# wl_phy_ctrl_secure register map
Vendor: Texas Instruments
Peripheral module from a debugger description file (folder CC35X1E).
Registers are 32-bit, access per field, no defined reset value unless marked. A register's access mark holds for its fields unless they carry their own. Offsets are as the file gives them; lines under a group give offsets from that group; [hi:lo] are bit positions; {n}, {i} and the like mark numbered series; 'fields as' and 'values as' point back to an identical list; <NAME> marks a mode.

## wl_phy_ctrl_secure
0x00 scr_src_addr reset 0x0 — Internal scripter registers affect the scripter on-going behavior.
  [15:0] MEM_SRC_ADDR_WROPT rw — Defines the current script base address. The scripter fetch bus will read consecutive rows from this address in increments of 4.
0x04 scr_dest_rd_offset_addr — Scripter Destination offset address
  [15:0] MEM_DEST_RD_OFFSET_ADDR rw — Set destination read address bits [31:16]. 4590 - PHY MCU RAMs 4591 - PHY MCU SCR RAM and Regs 4592 - PHY OCP interConnect components but MCU. Other - To SOC
0x08 scr_data_bit_sel reset 0x0 — Data bit select
  [15:0] MEM_DATA_BIT_SEL_WROPT rw — This field has 2 purposes: 1. Set the bits that will be changed in the next read modify write command. 2. Set the bits that will be checked in the next conditional write command.
0x0C scr_data_match reset 0xFFFF — Matching value for conditional write command.
  [15:0] MEM_DATA_MATCH_WROPT rw — This register is used for conditional write operations. This register needs to be defined and then a variable value is read and compared (according to the bits set in the data_bit_sel register). (Set the matching value for the next conditional write command)
0x10 scr_spare_1 reset 0x0
  [7:0] MEM_SCR_SPARE_1 rw
0x14 scr_wait_delay — Scripter Wait Delay Register
  [15:0] MEM_WAIT_DELAY_WROPT rw — Once this register is set to a non-zero value the scripter exe bus is suspended untill it decrements all the way back to zero.
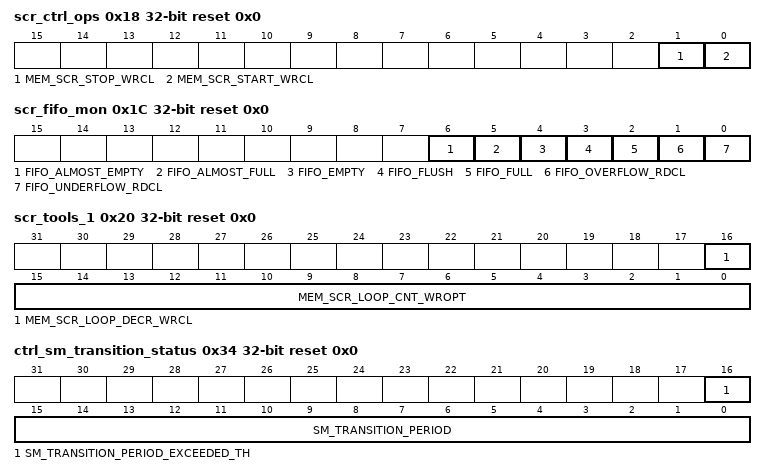
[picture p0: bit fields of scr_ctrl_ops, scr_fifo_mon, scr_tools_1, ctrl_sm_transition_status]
0x18 scr_ctrl_ops reset 0x0
  [1] MEM_SCR_STOP_WRCL wo — This bit must be set at the end of any script. It may also be used to abort a running script externally by FW.
  [0] MEM_SCR_START_WRCL wo — This pulse bit allows the FW to trigger the start of a script. The FW needs to per-set the value of the src_addr register.
0x1C scr_fifo_mon ro reset 0x0
  [6] FIFO_ALMOST_EMPTY, [5] FIFO_ALMOST_FULL, [4] FIFO_EMPTY, [3] FIFO_FLUSH, [2] FIFO_FULL, [1] FIFO_OVERFLOW_RDCL, [0] FIFO_UNDERFLOW_RDCL
0x20 scr_tools_1 reset 0x0
  [16] MEM_SCR_LOOP_DECR_WRCL wo, [15:0] MEM_SCR_LOOP_CNT_WROPT rw
0x24 scr_dest_wr_offset_addr — Scripter Destination offset address
  [15:0] MEM_DEST_WR_OFFSET_ADDR rw — Set destination write address bits [31:16]. 4590 - PHY MCU RAMs 4591 - PHY MCU SCR RAM and Regs 4592 - PHY OCP interConnect components but MCU. Other - To SOC
0x30 ctrl_sm_transition_threshold reset 0x1002
  [10:0] MEM_TRANSITION_TIME_TRACK_TH rw — Event Executer (cortex, scripter or both) transition time limit. When executer exeedes this value, SM_TRANSITION_PERIOD_EXCEEDED_TH is set high (clr by s/w). Counts up to 102.4us. Resolution is 0.8us. Default ix 0x2 (1.6us).
0x34 ctrl_sm_transition_status ro reset 0x0
  [16] SM_TRANSITION_PERIOD_EXCEEDED_TH — This indication is set when: SM_TRANSITION_PERIOD[in 25ns units]> SM_TRANSITION_PERIOD_TH
  [15:0] SM_TRANSITION_PERIOD — the period of time that is measured from the time an event is sent to cortex/scripter till the time cortex/scripter is done and phy state is changed. Time is measured at 25ns*32=800ns units (1.25M rate) (as if you concate 5 LSB equal to '0' on the right side of this number.)
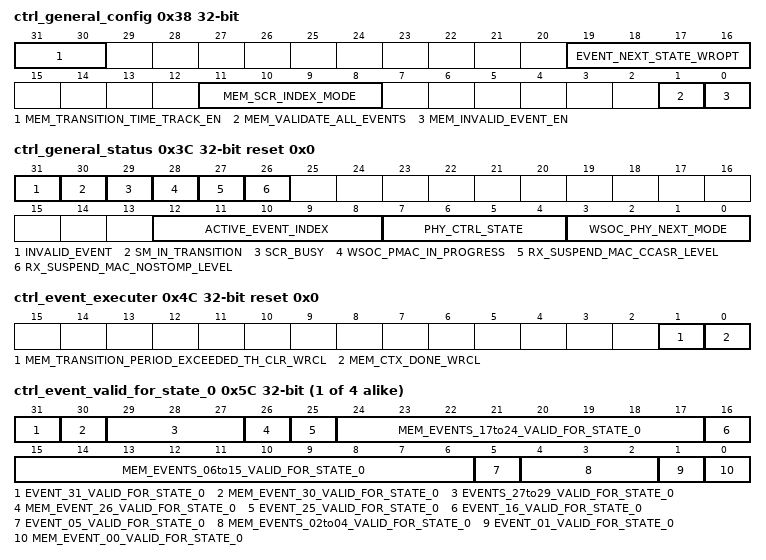
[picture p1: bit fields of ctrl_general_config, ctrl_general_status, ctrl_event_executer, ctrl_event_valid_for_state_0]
0x38 ctrl_general_config
  [31:30] MEM_TRANSITION_TIME_TRACK_EN rw — 00 - Do not measure transition time 01 - Measure CTX transition time 10 - Measure SCR transition time 11 - Measure CTX or SCR transition time (if both are excuted, measure till the last one finishes) note: time is measured @40M rate (each unit is 25ns)
  [19:16] EVENT_NEXT_STATE_WROPT rw — PHY Control FSM Bypass: This field will be loaded to PHY STATE immediately at acripter/cortex done. It replaces the default h/w next_state (that is selected per event at "evet start") .
  [11:8] MEM_SCR_INDEX_MODE rw — this mode controls the ADDR reg in SCR: 0 - ADDR is fetched from Upper-half[15:0] 1 - ADDR is fetched from Upper-half[31:16] 2 - ADDR is fetched from Lower-half[15:0] 3 - ADDR is fetched from Lower-half[31:16]
  [1] MEM_VALIDATE_ALL_EVENTS rw — '0' - invalid event will be ganarated according to event valid bit map (MEM_EVENT_VALID_FOR_STATE0..8) '1' - No invalid event support. All events are valid at any state regardless tovalid bit map.
  [0] MEM_INVALID_EVENT_EN rw — '0' - invalid event is not enabled. will not be sent to cortex. '1' - invalid event is enabled. will be sent to cortex.
0x3C ctrl_general_status ro reset 0x0
  [31] INVALID_EVENT — indication that invalid event is sent to cortex. This means that INVALID_EVENT_EN was set to 1.
  [30] SM_IN_TRANSITION — indication that an event is sent to cortex/scripter. and cortex/scripter is during execution. When done, phy state will be changed.
  [29] SCR_BUSY — This register indicates a script triggered by an executable event toward the scripter is currently running. For Script index refer to ACTIVE_EVENT_INDEX
  [28] WSOC_PMAC_IN_PROGRESS — Indication from SOC
  [27] RX_SUSPEND_MAC_CCASR_LEVEL — Rx suspend sideband status bit from MAC: indication of Spatial Reuse. This indication is cleared by Rx_Ctrl.suspend_end event
  [26] RX_SUSPEND_MAC_NOSTOMP_LEVEL — Rx suspend sideband status bit from MAC: indication that the suspend event that was set is of type NO STOMP This indication is cleared by Rx_Ctrl.suspend_end event
  [12:8] ACTIVE_EVENT_INDEX — Holds the index of current effective not masked event. The index is valid for reading as long as the event is active*. Once event handling is done (either trigering scr/ctx or not) this field holds last active event. *) An Active event is an event that is handles by h/w in one of the following ways: An non-mask event, for specific current PHY STATE, can be "non-valid", "valid and not executable" or "valid and exeutable" by scripter/cortex. If event is "non-valid" if INVALID_EVENT_EN = 1 it will trigger the cortex - index is held till cortex is done and event gets cleared. if INVALID_EVENT_EN = 0 it will only change PHY STATE to next state and event gets cleared. Else if "event is not executable" it will only change PHY State to next state - this field holds event index for few cycles till event gets cleared. Else ("valid and executable") It will trigger cortex/scripter. index is held till cortex/scripter are done and event gets cleared.
  [7:4] PHY_CTRL_STATE — Holds the current state of the operational PHY CTRL FSM.
  [3:0] WSOC_PHY_NEXT_MODE — Input from SOC that indicates the mode to move to upon wsoc_change_mode or wsoc_change_mode_with_abort are set.
0x40 ctrl_event_mask rw
  [31:0] MEM_EVENT_MASK — Each bit set to '1' will mask the corresponding event from changing PHY state and/or triggering script/cortex. Events are indexed as follow: 0 - Reserved 1 - tx_header_rise 2 - rxt_stomp_ind_for_ctrl 3 - wsoc_change_mode_rise 4 - wsoc_change_mode_abort_rise 5 - wsoc_cmd_rise 6 - phy_dma_done 7 - rx_last 8 - tx_active_fall 9 - wsoc_rx_abort_rise 10 - wsoc_pmac_not_in_progress 11 - rx_suspend_rcmnd 12 - ls_reject 13 - plcp_hdr_err 14 - rx_bd 15 - rx_ctrl_select_11b 16 - timer_irq 17 - tx_multi 18 - rx_ctrl_td_eop 19 - trigger_frame_ind_rise 20 - rx_pd_rise 21 - rx_multi 22 - coex_busy 23 - wsoc_tx_mute_rise 24 - rx_suspend_end 25 - wsoc_event_done_rise 26 - rx_unsupported 27 - gp_adc_event 28 - nw_ip_gpio_1_tgl 29 - nw_ip_gpio_2_tgl 30 - ana_pa_dc2dc_ready_rise 31 - ocla_triger_rise
0x44 ctrl_event_ctx_mask rw reset 0x8594FFC5
  [31:0] MEM_EVENT_CTX_MASK — Defines whether a specific event is executable and will be sent (IRQ) to cortex. 0 - event is not masked. will be sent to cortex. 1 - event is masked. will not be sent to cortex. *Events Bit map is the same as specified at MEM_EVENT_MASK
0x48 ctrl_event_scr_mask rw reset 0xFE7F04BE
  [31:0] MEM_EVENT_SCR_MASK — Defines whether a specific event is executable and will be sent (IRQ) to scripter. 0 - event is not masked. will be sent to scripter. 1 - event is masked. will not be sent to scripter. *Events Bit map is the same as specified at MEM_EVENT_MASK
0x4C ctrl_event_executer reset 0x0
  [1] MEM_TRANSITION_PERIOD_EXCEEDED_TH_CLR_WRCL wo
  [0] MEM_CTX_DONE_WRCL wo — Cortex Done indication. When this pulse is set, the executable event is done and h/w chenges PHY STATE.
0x50 ctrl_event_status_set wo reset 0x0 — Setting a bit in this register sets corresponding bit in status reg. It is equivalent to the occurence of an HW event.
  [31:0] MEM_STATUS_SET_WRCL
0x54 ctrl_event_status_clr wo reset 0x0 — Setting a bit in this register clears the corresponding bit in the status register.
  [31:0] MEM_STATUS_CLR_WRCL
0x58 ctrl_event_status ro reset 0x0 — This registers latches events that are not masked. The event stays latched till automatically cleared once the event is handled. (Either non-valid, valid but not executable or executable).
{0x5C+4i} ctrl_event_valid_for_state_{i} (i=0..3) — Defines whether a specific event is valid for this PHY State. 0 - event is not valid. 1 - event is valid. *Events Bit map (Events vs. Index) is the same as specified at MEM_EVENT_MASK *Events 1,5,16,25,27-29 and 31 are always "Valid" for this state (equal to "1". Hard-wired by h/w)
  [31] EVENT_31_VALID_FOR_STATE_{i} ro — always 1 - hw "hard wired".
  [30] MEM_EVENT_30_VALID_FOR_STATE_{i} rw
  [29:27] EVENTS_27to29_VALID_FOR_STATE_{i} ro — always 1 - hw "hard wired".
  [26] MEM_EVENT_26_VALID_FOR_STATE_{i} rw
  [25] EVENT_25_VALID_FOR_STATE_{i} ro — always 1 - hw "hard wired".
  [24:17] MEM_EVENTS_17to24_VALID_FOR_STATE_{i} rw
  [16] EVENT_16_VALID_FOR_STATE_{i} ro — always 1 - hw "hard wired".
  [15:6] MEM_EVENTS_06to15_VALID_FOR_STATE_{i} rw
  [5] EVENT_05_VALID_FOR_STATE_{i} ro — always 1 - hw "hard wired".
  [4:2] MEM_EVENTS_02to04_VALID_FOR_STATE_{i} rw
  [1] EVENT_01_VALID_FOR_STATE_{i} ro — always 1 - hw "hard wired".
  [0] MEM_EVENT_00_VALID_FOR_STATE_{i} rw
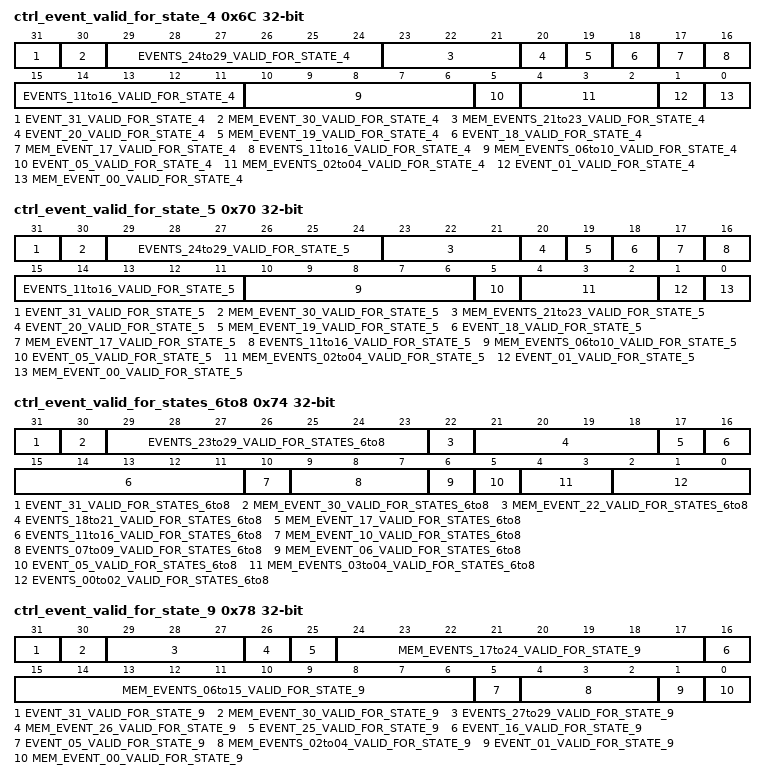
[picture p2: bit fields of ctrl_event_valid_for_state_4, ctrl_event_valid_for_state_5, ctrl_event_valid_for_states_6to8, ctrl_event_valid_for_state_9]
0x6C ctrl_event_valid_for_state_4 — Defines whether a specific event is valid for this PHY State. 0 - event is not valid. 1 - event is valid. *Events Bit map is the same as specified at MEM_EVENT_MASK *Events 1, 5, 16, 25, 27-9, and 31 are always Valid for this state (Equal to "1". Hard-wired by h/w) *Events 11-15, 18, 20, 24 and 26 are always Not Valid for this state (Equal to "0". Hard-wired by h/w)
  [31] EVENT_31_VALID_FOR_STATE_4 ro — Events 31 always 1 - hw "hard wired".
  [30] MEM_EVENT_30_VALID_FOR_STATE_4 rw
  [29:24] EVENTS_24to29_VALID_FOR_STATE_4 ro — Event 24 always 0 - hw "hard wired". Event 25 always 1 - hw "hard wired". Event 26 always 0 - hw "hard wired". Event 27 always 1 - hw "hard wired". Event 28 always 1 - hw "hard wired". Event 29 always 1 - hw "hard wired".
  [23:21] MEM_EVENTS_21to23_VALID_FOR_STATE_4 rw
  [20] EVENT_20_VALID_FOR_STATE_4 ro — Events 20 always 0 - hw "hard wired".
  [19] MEM_EVENT_19_VALID_FOR_STATE_4 rw
  [18] EVENT_18_VALID_FOR_STATE_4 ro — Events 18 always 0 - hw "hard wired".
  [17] MEM_EVENT_17_VALID_FOR_STATE_4 rw
  [16:11] EVENTS_11to16_VALID_FOR_STATE_4 ro — Events 11-15 always 0 - hw "hard wired". Event 16 always 1 - hw "hard wired".
  [10:6] MEM_EVENTS_06to10_VALID_FOR_STATE_4 rw
  [5] EVENT_05_VALID_FOR_STATE_4 ro — Event 5 always 1 - hw "hard wired".
  [4:2] MEM_EVENTS_02to04_VALID_FOR_STATE_4 rw
  [1] EVENT_01_VALID_FOR_STATE_4 ro — Event 1 always 1 - hw "hard wired".
  [0] MEM_EVENT_00_VALID_FOR_STATE_4 rw
0x70 ctrl_event_valid_for_state_5 — Defines whether a specific event is valid for this PHY State. 0 - event is not valid. 1 - event is valid. *Events Bit map is the same as specified at MEM_EVENT_MASK *Events 1, 5, 16, 25, 27-9, and 31 are always Valid for this state (Equal to "1". Hard-wired by h/w) *Events 11-15, 18, 20, 24 and 26 are always Not Valid for this state (Equal to "0". Hard-wired by h/w)
  [31] EVENT_31_VALID_FOR_STATE_5 ro — Events 31 always 1 - hw "hard wired".
  [30] MEM_EVENT_30_VALID_FOR_STATE_5 rw
  [29:24] EVENTS_24to29_VALID_FOR_STATE_5 ro — Event 24 always 0 - hw "hard wired". Event 25 always 1 - hw "hard wired". Event 26 always 0 - hw "hard wired". Event 27 always 1 - hw "hard wired". Event 28 always 1 - hw "hard wired". Event 29 always 1 - hw "hard wired".
  [23:21] MEM_EVENTS_21to23_VALID_FOR_STATE_5 rw
  [20] EVENT_20_VALID_FOR_STATE_5 ro — Events 20 always 0 - hw "hard wired".
  [19] MEM_EVENT_19_VALID_FOR_STATE_5 rw
  [18] EVENT_18_VALID_FOR_STATE_5 ro — Events 18 always 0 - hw "hard wired".
  [17] MEM_EVENT_17_VALID_FOR_STATE_5 rw
  [16:11] EVENTS_11to16_VALID_FOR_STATE_5 ro — Events 11-15 always 0 - hw "hard wired". Event 16 always 1 - hw "hard wired".
  [10:6] MEM_EVENTS_06to10_VALID_FOR_STATE_5 rw
  [5] EVENT_05_VALID_FOR_STATE_5 ro — Event 5 always 1 - hw "hard wired".
  [4:2] MEM_EVENTS_02to04_VALID_FOR_STATE_5 rw
  [1] EVENT_01_VALID_FOR_STATE_5 ro — Event 1 always 1 - hw "hard wired".
  [0] MEM_EVENT_00_VALID_FOR_STATE_5 rw
0x74 ctrl_event_valid_for_states_6to8 — Defines whether a specific event is valid for this PHY State (non-active states: standby, idle and prepared to sleep). 0 - event is not valid. 1 - event is valid. *Events Bit map is the same as specified at MEM_EVENT_MASK *Events 5 and 25 are always equal to "1" (hard-wired by h/w)
  [31] EVENT_31_VALID_FOR_STATES_6to8 ro — Event 31 always 1 - hw "hard wired".
  [30] MEM_EVENT_30_VALID_FOR_STATES_6to8 rw
  [29:23] EVENTS_23to29_VALID_FOR_STATES_6to8 ro — Event 23 always 0 - hw "hard wired". Event 24 always 0 - hw "hard wired". Event 25 always 1 - hw "hard wired". Event 26 always 0 - hw "hard wired". Event 27 always 1 - hw "hard wired". Event 28 always 1 - hw "hard wired". Event 29 always 1 - hw "hard wired".
  [22] MEM_EVENT_22_VALID_FOR_STATES_6to8 rw
  [21:18] EVENTS_18to21_VALID_FOR_STATES_6to8 ro — Events 18-21 always 0 - hw "hard wired".
  [17] MEM_EVENT_17_VALID_FOR_STATES_6to8 rw
  [16:11] EVENTS_11to16_VALID_FOR_STATES_6to8 ro — Events 11-15 always 0 - hw "hard wired". Event 16 always 1 - hw "hard wired".
  [10] MEM_EVENT_10_VALID_FOR_STATES_6to8 rw
  [9:7] EVENTS_07to09_VALID_FOR_STATES_6to8 ro — Event 7-9 always 0 - hw "hard wired".
  [6] MEM_EVENT_06_VALID_FOR_STATES_6to8 rw
  [5] EVENT_05_VALID_FOR_STATES_6to8 ro — Event 5 always 1 - hw "hard wired".
  [4:3] MEM_EVENTS_03to04_VALID_FOR_STATES_6to8 rw
  [2:0] EVENTS_00to02_VALID_FOR_STATES_6to8 ro — Event 0 is always 0 - hw "hard wired". Event 1 is always 1 - hw "hard wired". Event 2 is always 0 - hw "hard wired".
0x78 ctrl_event_valid_for_state_9 — Defines whether a specific event is valid for this PHY State. 0 - event is not valid. 1 - event is valid. *Events Bit map (Events vs. Index) is the same as specified at MEM_EVENT_MASK *Events 1,5,16,25,27-29 and 31 are always "Valid" for this state (equal to "1". Hard-wired by h/w)
  [31] EVENT_31_VALID_FOR_STATE_9 ro — always 1 - hw "hard wired".
  [30] MEM_EVENT_30_VALID_FOR_STATE_9 rw
  [29:27] EVENTS_27to29_VALID_FOR_STATE_9 ro — always 1 - hw "hard wired".
  [26] MEM_EVENT_26_VALID_FOR_STATE_9 rw
  [25] EVENT_25_VALID_FOR_STATE_9 ro — always 1 - hw "hard wired".
  [24:17] MEM_EVENTS_17to24_VALID_FOR_STATE_9 rw
  [16] EVENT_16_VALID_FOR_STATE_9 ro — always 1 - hw "hard wired".
  [15:6] MEM_EVENTS_06to15_VALID_FOR_STATE_9 rw
  [5] EVENT_05_VALID_FOR_STATE_9 ro — always 1 - hw "hard wired".
  [4:2] MEM_EVENTS_02to04_VALID_FOR_STATE_9 rw
  [1] EVENT_01_VALID_FOR_STATE_9 ro — always 1 - hw "hard wired".
  [0] MEM_EVENT_00_VALID_FOR_STATE_9 rw
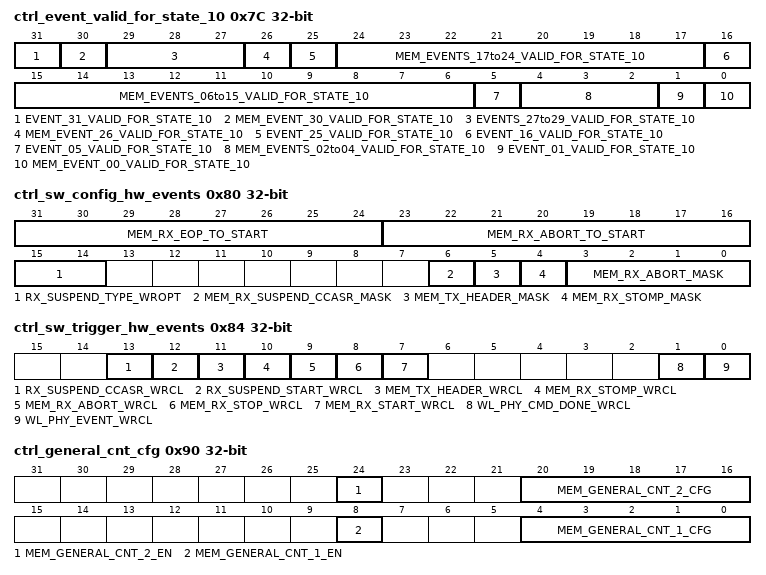
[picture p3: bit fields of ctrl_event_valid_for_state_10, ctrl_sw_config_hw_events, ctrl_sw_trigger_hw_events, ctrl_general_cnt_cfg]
0x7C ctrl_event_valid_for_state_10 — Defines whether a specific event is valid for this PHY State. 0 - event is not valid. 1 - event is valid. *Events Bit map (Events vs. Index) is the same as specified at MEM_EVENT_MASK *Events 1,5,16,25,27-29 and 31 are always "Valid" for this state (equal to "1". Hard-wired by h/w)
  [31] EVENT_31_VALID_FOR_STATE_10 ro — always 1 - hw "hard wired".
  [30] MEM_EVENT_30_VALID_FOR_STATE_10 rw
  [29:27] EVENTS_27to29_VALID_FOR_STATE_10 ro — always 1 - hw "hard wired".
  [26] MEM_EVENT_26_VALID_FOR_STATE_10 rw
  [25] EVENT_25_VALID_FOR_STATE_10 ro — always 1 - hw "hard wired".
  [24:17] MEM_EVENTS_17to24_VALID_FOR_STATE_10 rw
  [16] EVENT_16_VALID_FOR_STATE_10 ro — always 1 - hw "hard wired".
  [15:6] MEM_EVENTS_06to15_VALID_FOR_STATE_10 rw
  [5] EVENT_05_VALID_FOR_STATE_10 ro — always 1 - hw "hard wired".
  [4:2] MEM_EVENTS_02to04_VALID_FOR_STATE_10 rw
  [1] EVENT_01_VALID_FOR_STATE_10 ro — always 1 - hw "hard wired".
  [0] MEM_EVENT_00_VALID_FOR_STATE_10 rw
0x80 ctrl_sw_config_hw_events — This register masks the h/w events. It also sets the time between abort/eop to rx start (if any).
  [31:24] MEM_RX_EOP_TO_START rw — Defines the delay between rx_eop rising and rx_start. Valid range 1-255 (in 25ns steps). Setting 0 to this reg means no rx start is issued after rx eop.
  [23:16] MEM_RX_ABORT_TO_START rw — Defines the delay between rx_abort rising and rx_start. Valid range 1-255 (in 25ns steps). Setting 0 to this reg means no rx start is issued after rx abort.
  [15:14] RX_SUSPEND_TYPE_WROPT rw — Rx Suspend Type decision to Rx Ctrl: 0 - do not shut-off Ana or PLL 1 - shuf-off Analog 2 - shut-off PLL By default (@suspend pulse from Rx Ctrl) the Type is loaded with Rx Ctrl recommendation.
  [6] MEM_RX_SUSPEND_CCASR_MASK rw — Mask RX Suspend Spatial Reuse from MAC
  [5] MEM_TX_HEADER_MASK rw — '0' - tx header be set in tx control H/W when tx_header from MAC is set. '1' - tx_header is masked. Will not be set when tx_header from MAC is set.
  [4] MEM_RX_STOMP_MASK rw — '1' - rx_stomp will not be raised immediately after rx_stomp indication from IEM.
  [3:0] MEM_RX_ABORT_MASK rw — Masks the abort sources. If the mask bit is set the rx_abort will not be raised automatically. Abort sources: 0 - plcp_hdr_err, 1 - tx_header_rise, 2 - ls_reject.
0x84 ctrl_sw_trigger_hw_events — This register is responsible of the generation of: Rx abort, Rx stomp, Rx start, Phy Event and Phy conmmand done indications.
  [13] RX_SUSPEND_CCASR_WRCL wo — Override value for RX Suspend Spatial Reuse from MAC
  [12] RX_SUSPEND_START_WRCL wo — FW triggers Rx Suspend pulse (40M) toward Rx Ctrl. Also used to set the suspend-start level indication (e.g. toward the CCA)
  [11] MEM_TX_HEADER_WRCL wo — FW triggered tx_header pulse. This pulse is extended to @20M as tx_ctrl (i/f to mac) currently works @20M
  [10] MEM_RX_STOMP_WRCL wo — FW triggered rx_stomp pulse.
  [9] MEM_RX_ABORT_WRCL wo — FW triggered rx_abort pulse.
  [8] MEM_RX_STOP_WRCL wo — FW triggered rx_abort pulse. No rx start is followed.
  [7] MEM_RX_START_WRCL wo — FW triggered rx_start pulse.
  [1] WL_PHY_CMD_DONE_WRCL wo — PHY to SOC command done indication. PHY finish handling SOC command.
  [0] WL_PHY_EVENT_WRCL wo — PHY to SOC Event
0x88 ctrl_general_cnt_1
  [15:0] MEM_GENERAL_CNT_1_WROPT rw — Genetal event counter. The event is one of the 32 events the PHY control use The select of event is using field "MEM_GENERLA_CNT_1_CFG
0x8C ctrl_general_cnt_2
  [15:0] MEM_GENERAL_CNT_2_WROPT rw — Genetal event counter. The event is one of the 32 events the PHY control use The select of event is using field "MEM_GENERLA_CNT_2_CFG
0x90 ctrl_general_cnt_cfg
  [24] MEM_GENERAL_CNT_2_EN rw — Enable for GENERAL_CNT_2
  [20:16] MEM_GENERAL_CNT_2_CFG rw — Select the event for GENERAL_CNT_2 For event detail please refer to PHY Control spec Doc
  [8] MEM_GENERAL_CNT_1_EN rw — Enable for GENERAL_CNT_1
  [4:0] MEM_GENERAL_CNT_1_CFG rw — Select the event for GENERAL_CNT_1 For event detail please refer to PHY Control spec Doc
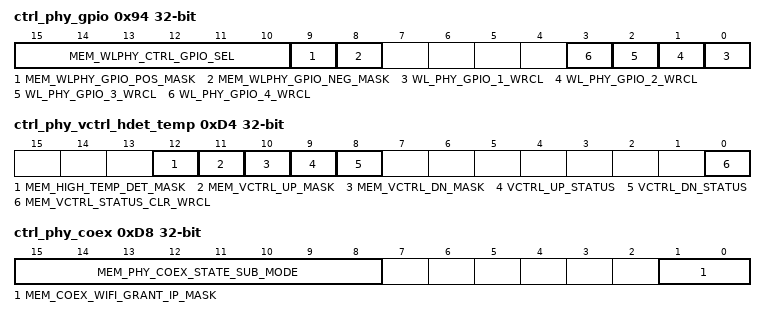
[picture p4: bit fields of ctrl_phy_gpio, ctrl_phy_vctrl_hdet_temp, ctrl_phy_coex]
0x94 ctrl_phy_gpio
  [15:10] MEM_WLPHY_CTRL_GPIO_SEL rw — GPIO selector : 0 - select gpio 0 1 - select gpio 1 ... 45 - select gpio 45 46-63 No GPIO is selectes, Effectively it means Mask GPIO
  [9] MEM_WLPHY_GPIO_POS_MASK rw
  [8] MEM_WLPHY_GPIO_NEG_MASK rw
  [n-1] WL_PHY_GPIO_{n}_WRCL wo (n=1..4)
0xA0 ctrl_spare_1 rw reset 0x0
  [31:0] MEM_CTRL_SPARE_1
0xA4 ctrl_spare_2 rw reset 0x0
  [31:0] MEM_CTRL_SPARE_2
0xB0 rx_multi_event_mask
  [23:0] MEM_RX_MULTI_EVENT_MASK rw — Each bit set to '1' will mask the corresponding RX CTRL event from changing PHY state and/or triggering script/cortex. Events are indexed as follow: 0 - vd_sig_done 1 - rx_header_rise 2 - bs_rise 3 - bs_fall 4 - pd_dismiss 5 - td_ack_done 6 - rx_dc_clip 7 - rx_11ax_td_data_eop 8 - radar_pattern_detect 9 - pll_relock_clac_done 10- ed_high 11- cca_cs_with_energy 12- phy_cca 13- qual_cca 14- ch_traffic_est_done 15- rx_suspend_mac 16-23 - Reserved
0xB4 rx_multi_event_status_set reset 0x0 — Setting a bit in this register sets corresponding bit in rx ctrl status reg. It is equivalent to the occurence of an HW event.
  [23:0] MEM_RX_MULTI_STATUS_SET_WRCL wo
0xB8 rx_multi_event_status_clr reset 0x0 — Setting a bit in this register clears the corresponding bit in the rx ctrl status register.
  [23:0] MEM_RX_MULTI_STATUS_CLR_WRCL wo
0xBC rx_multi_event_status ro reset 0x0 — This registers latches Rx Ctrl events that are not masked. The event stays latched till clr by S/w (not automatically cleared).
  [23:0] RX_MULTI_STATUS
0xC0 tx_multi_event_mask
  [7:0] MEM_TX_MULTI_EVENT_MASK rw — Each bit set to '1' will mask the corresponding TX events from changing PHY state and/or triggering script/cortex. Events are indexed as follow: 0 Tx HDR Fall 1 RFNL Mul clip irq 2 Tx clibration Seq IRQ 3 Aux Rx Required 4-7 Reserved
0xC4 tx_multi_event_status_set reset 0x0 — Setting a bit in this register sets corresponding bit in tx multi status reg. It is equivalent to the occurence of an HW event.
  [7:0] MEM_TX_MULTI_STATUS_SET_WRCL wo
0xC8 tx_multi_event_status_clr reset 0x0 — Setting a bit in this register clears the corresponding bit in the tx multi status register.
  [7:0] MEM_TX_MULTI_STATUS_CLR_WRCL wo
0xCC tx_multi_event_status ro reset 0x0 — This registers latches Tx Multi events that are not masked. The event stays latched till clr by S/w (not automatically cleared).
  [7:0] TX_MULTI_STATUS
0xD0 scr_ble_event_mode ro reset 0x0
  [2:0] scr_ble_event_mode — the period of time that is measured from the time an event is sent to cortex/scripter till the time cortex/scripter is done and phy state is changed. Time is measured at 25ns*32=800ns units (1.25M rate) (as if you concate 5 LSB equal to '0' on the right side of this number.)
0xD4 ctrl_phy_vctrl_hdet_temp
  [12] MEM_HIGH_TEMP_DET_MASK rw, [11] MEM_VCTRL_UP_MASK rw, [10] MEM_VCTRL_DN_MASK rw, [9] VCTRL_UP_STATUS ro, [8] VCTRL_DN_STATUS ro, [0] MEM_VCTRL_STATUS_CLR_WRCL wo
0xD8 ctrl_phy_coex
  [15:8] MEM_PHY_COEX_STATE_SUB_MODE rw — This register will hold information regarding the PHY PM mode and sub-modes when PHY state is Coex
  [1:0] MEM_COEX_WIFI_GRANT_IP_MASK rw — bit 0 - grant bit 1 - degrant '1' - mask event '0' - do not mask, will cause event
0xDC coex_wifi_grant_status
  [0] COEX_WIFI_GRANT_IP_STATUS_WROPT rw — '1' - grant - rise detect
0xE0 coex_wifi_degrant_status
  [0] COEX_WIFI_DEGRANT_IP_STATUS_WROPT rw — '1' - degrant - fall detect
